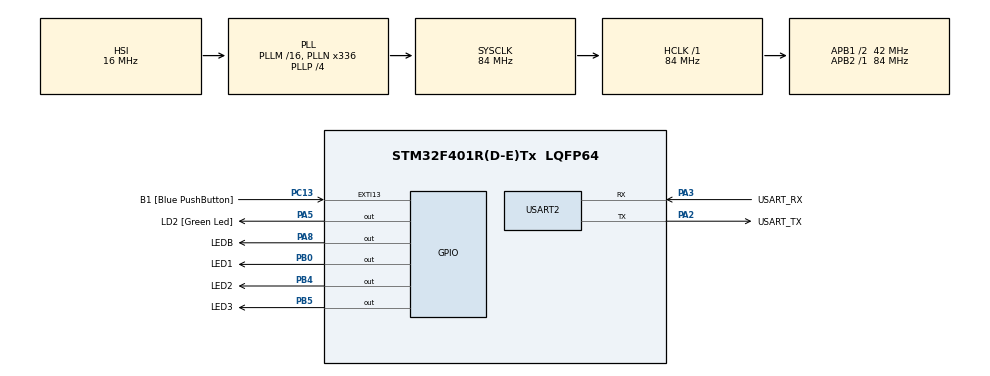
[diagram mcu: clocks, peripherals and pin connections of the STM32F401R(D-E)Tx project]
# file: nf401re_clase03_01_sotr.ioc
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Mcu.Family=STM32F4
PA2.GPIO_PuPd=GPIO_NOPULL
RCC.CortexFreq_Value=84000000
PA14.GPIO_Label=TCK
PA3.GPIO_PuPd=GPIO_NOPULL
PA2.GPIO_Speed=GPIO_SPEED_FREQ_LOW
PB0.GPIO_Label=LED1
PA3.GPIO_Speed=GPIO_SPEED_FREQ_LOW
RCC.SYSCLKSource=RCC_SYSCLKSOURCE_PLLCLK
ProjectManager.StackSize=0x400
VP_FREERTOS_VS_CMSIS_V2.Mode=CMSIS_V2
PH0\ -\ OSC_IN.Signal=RCC_OSC_IN
RCC.HCLKFreq_Value=84000000
RCC.APB2TimFreq_Value=84000000
RCC.AHBFreq_Value=84000000
RCC.HSE_VALUE=8000000
PC13-ANTI_TAMP.Signal=GPXTI13
PC14-OSC32_IN.Mode=LSE-External-Oscillator
PA14.Mode=Serial_Wire
VP_SYS_VS_tim1.Mode=TIM1
PA5.GPIO_PuPd=GPIO_NOPULL
PA8.Signal=GPIO_Output
Mcu.Package=LQFP64
NVIC.TimeBase=TIM1_UP_TIM10_IRQn
USART2.VirtualMode=VM_ASYNC
PA2.GPIO_Label=USART_TX
NVIC.TimeBaseIP=TIM1
PB5.GPIO_Label=LED3
RCC.APB1TimFreq_Value=84000000
PB4.Signal=GPIO_Output
PA3.Signal=USART2_RX
PA2.GPIO_Mode=GPIO_MODE_AF_PP
PB3.GPIO_Label=SWO
PC15-OSC32_OUT.Mode=LSE-External-Oscillator
FREERTOS.Tasks01=defaultTask,24,128,StartDefaultTask,Default,NULL,Dynamic,NULL,NULL
PC13-ANTI_TAMP.GPIO_PuPd=GPIO_NOPULL
PC13-ANTI_TAMP.GPIO_Label=B1 [Blue PushButton]
PH1\ -\ OSC_OUT.Mode=HSE-External-Clock-Source
RCC.APB1CLKDivider=RCC_HCLK_DIV2
PC14-OSC32_IN.Signal=RCC_OSC32_IN
PA13.Signal=SYS_JTMS-SWDIO
PA3.Mode=Asynchronous
PH0\ -\ OSC_IN.Mode=HSE-External-Clock-Source
PA8.GPIO_Label=LEDB
ProjectManager.TargetToolchain=STM32CubeIDE
PA3.GPIO_Mode=GPIO_MODE_AF_PP
PC15-OSC32_OUT.Signal=RCC_OSC32_OUT
PA5.Signal=GPIO_Output
PH1\ -\ OSC_OUT.Signal=RCC_OSC_OUT
board=NUCLEO-F401RE
RCC.VCOOutputFreq_Value=336000000
RCC.APB2Freq_Value=84000000
PB4.GPIO_Label=LED2
PA13.Mode=Serial_Wire
Mcu.Name=STM32F401R(D-E)Tx
PA13.GPIO_Label=TMS
PA2.Signal=USART2_TX
RCC.48MHZClocksFreq_Value=48000000
PB3.Signal=SYS_JTDO-SWO
RCC.SYSCLKFreq_VALUE=84000000
PB5.Signal=GPIO_Output
PA5.GPIO_Label=LD2 [Green Led]
PC13-ANTI_TAMP.GPIO_ModeDefaultEXTI=GPIO_MODE_IT_FALLING
PA14.Signal=SYS_JTCK-SWCLK
ProjectManager.HeapSize=0x200
NVIC.TIM1_UP_TIM10_IRQn=true\:0\:0\:false\:false\:true\:false\:false\:true
RCC.HSI_VALUE=16000000
RCC.PLLP=RCC_PLLP_DIV4
PA5.GPIO_Speed=GPIO_SPEED_FREQ_LOW
RCC.PLLQ=7
NVIC.PriorityGroup=NVIC_PRIORITYGROUP_4
RCC.PLLN=336
PA2.Mode=Asynchronous
RCC.APB1Freq_Value=42000000
PA5.GPIO_Mode=GPIO_MODE_OUTPUT_PP
PB0.Signal=GPIO_Output
PA3.GPIO_Label=USART_RX

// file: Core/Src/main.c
/* USER CODE BEGIN Header */
/**
  ******************************************************************************
  * @file           : main.c
  * @brief          : Main program body
  ******************************************************************************
  * @attention
  *
  * <h2><center>&copy; Copyright (c) 2021 STMicroelectronics.
  * All rights reserved.</center></h2>
  *
  * This software component is licensed by ST under BSD 3-Clause license,
  * the "License"; You may not use this file except in compliance with the
  * License. You may obtain a copy of the License at:
  *                        opensource.org/licenses/BSD-3-Clause
  *
  ******************************************************************************
  */
/* USER CODE END Header */
#include "main.h"
//#include "cmsis_os.h"

/* USER CODE BEGIN Includes */
#include "FreeRTOS.h"
#include "task.h"
#include "FreeRTOSConfig.h"
//#include "sapi.h"

/* USER CODE END Includes */

UART_HandleTypeDef huart2;

/* Definitions for defaultTask */
/*osThreadId_t defaultTaskHandle;
const osThreadAttr_t defaultTask_attributes = {
  .name = "defaultTask",
  .stack_size = 128 * 4,
  .priority = (osPriority_t) osPriorityNormal,
};*/

void SystemClock_Config(void);
static void MX_GPIO_Init(void);
static void MX_USART2_UART_Init(void);
void StartDefaultTask(void *argument);

/* USER CODE BEGIN PFP */
void heart_beat(void * parameters); /*Prendo A - apago A*/
/* USER CODE END PFP */

int main(void)
{

  /* MCU Configuration--------------------------------------------------------*/

  /* Reset of all peripherals, Initializes the Flash interface and the Systick. */
  HAL_Init();

  /* Configure the system clock */
  SystemClock_Config();

  /* Initialize all configured peripherals */
  MX_GPIO_Init();
  MX_USART2_UART_Init();

  /* Init scheduler */
  osKernelInitialize();

  /* Create the thread(s) */
  /* creation of defaultTask */
  /*defaultTaskHandle = osThreadNew(StartDefaultTask, NULL, &defaultTask_attributes);*/

  /* USER CODE BEGIN RTOS_THREADS */
  /* add threads, ... */
  BaseType_t res = xTaskCreate(heart_beat, (const char*) "heart_beat", 2*configMINIMAL_STACK_SIZE, 0, tskIDLE_PRIORITY+1, 0);
  if(res == pdFAIL){
	  HAL_GPIO_WritePin(LD2_GPIO_Port, LD2_Pin, GPIO_PIN_SET);
  }
  configASSERT(res == pdPASS);

  /* USER CODE END RTOS_THREADS */

  /* Start scheduler */
  osKernelStart();

  /* We should never get here as control is now taken by the scheduler */
  /* Infinite loop */
  while (1)
  {

  }
}

void SystemClock_Config(void)
{
  RCC_OscInitTypeDef RCC_OscInitStruct = {0};
  RCC_ClkInitTypeDef RCC_ClkInitStruct = {0};

  /** Configure the main internal regulator output voltage
  */
  __HAL_RCC_PWR_CLK_ENABLE();
  __HAL_PWR_VOLTAGESCALING_CONFIG(PWR_REGULATOR_VOLTAGE_SCALE2);
  /** Initializes the RCC Oscillators according to the specified parameters
  * in the RCC_OscInitTypeDef structure.
  */
  RCC_OscInitStruct.OscillatorType = RCC_OSCILLATORTYPE_HSI;
  RCC_OscInitStruct.HSIState = RCC_HSI_ON;
  RCC_OscInitStruct.HSICalibrationValue = RCC_HSICALIBRATION_DEFAULT;
  RCC_OscInitStruct.PLL.PLLState = RCC_PLL_ON;
  RCC_OscInitStruct.PLL.PLLSource = RCC_PLLSOURCE_HSI;
  RCC_OscInitStruct.PLL.PLLM = 16;
  RCC_OscInitStruct.PLL.PLLN = 336;
  RCC_OscInitStruct.PLL.PLLP = RCC_PLLP_DIV4;
  RCC_OscInitStruct.PLL.PLLQ = 7;
  if (HAL_RCC_OscConfig(&RCC_OscInitStruct) != HAL_OK)
  {
    Error_Handler();
  }
  /** Initializes the CPU, AHB and APB buses clocks
  */
  RCC_ClkInitStruct.ClockType = RCC_CLOCKTYPE_HCLK|RCC_CLOCKTYPE_SYSCLK
                              |RCC_CLOCKTYPE_PCLK1|RCC_CLOCKTYPE_PCLK2;
  RCC_ClkInitStruct.SYSCLKSource = RCC_SYSCLKSOURCE_PLLCLK;
  RCC_ClkInitStruct.AHBCLKDivider = RCC_SYSCLK_DIV1;
  RCC_ClkInitStruct.APB1CLKDivider = RCC_HCLK_DIV2;
  RCC_ClkInitStruct.APB2CLKDivider = RCC_HCLK_DIV1;

  if (HAL_RCC_ClockConfig(&RCC_ClkInitStruct, FLASH_LATENCY_2) != HAL_OK)
  {
    Error_Handler();
  }
}

static void MX_USART2_UART_Init(void)
{

  huart2.Instance = USART2;
  huart2.Init.BaudRate = 115200;
  huart2.Init.WordLength = UART_WORDLENGTH_8B;
  huart2.Init.StopBits = UART_STOPBITS_1;
  huart2.Init.Parity = UART_PARITY_NONE;
  huart2.Init.Mode = UART_MODE_TX_RX;
  huart2.Init.HwFlowCtl = UART_HWCONTROL_NONE;
  huart2.Init.OverSampling = UART_OVERSAMPLING_16;
  if (HAL_UART_Init(&huart2) != HAL_OK)
  {
    Error_Handler();
  }

}

static void MX_GPIO_Init(void)
{
  GPIO_InitTypeDef GPIO_InitStruct = {0};

  /* GPIO Ports Clock Enable */
  __HAL_RCC_GPIOC_CLK_ENABLE();
  __HAL_RCC_GPIOH_CLK_ENABLE();
  __HAL_RCC_GPIOA_CLK_ENABLE();
  __HAL_RCC_GPIOB_CLK_ENABLE();

  /*Configure GPIO pin Output Level */
  HAL_GPIO_WritePin(GPIOA, LD2_Pin|LEDB_Pin, GPIO_PIN_RESET);

  /*Configure GPIO pin Output Level */
  HAL_GPIO_WritePin(GPIOB, LED1_Pin|LED2_Pin|LED3_Pin, GPIO_PIN_RESET);

  /*Configure GPIO pin : B1_Pin */
  GPIO_InitStruct.Pin = B1_Pin;
  GPIO_InitStruct.Mode = GPIO_MODE_IT_FALLING;
  GPIO_InitStruct.Pull = GPIO_NOPULL;
  HAL_GPIO_Init(B1_GPIO_Port, &GPIO_InitStruct);

  /*Configure GPIO pins : LD2_Pin LEDB_Pin */
  GPIO_InitStruct.Pin = LD2_Pin|LEDB_Pin;
  GPIO_InitStruct.Mode = GPIO_MODE_OUTPUT_PP;
  GPIO_InitStruct.Pull = GPIO_NOPULL;
  GPIO_InitStruct.Speed = GPIO_SPEED_FREQ_LOW;
  HAL_GPIO_Init(GPIOA, &GPIO_InitStruct);

  /*Configure GPIO pins : LED1_Pin LED2_Pin LED3_Pin */
  GPIO_InitStruct.Pin = LED1_Pin|LED2_Pin|LED3_Pin;
  GPIO_InitStruct.Mode = GPIO_MODE_OUTPUT_PP;
  GPIO_InitStruct.Pull = GPIO_NOPULL;
  GPIO_InitStruct.Speed = GPIO_SPEED_FREQ_LOW;
  HAL_GPIO_Init(GPIOB, &GPIO_InitStruct);

}

/* USER CODE BEGIN 4 */
void heart_beat(void * parameters){
	/*Inicializacion*/

	/*Repetir por siempre*/
	for(;;){
		HAL_GPIO_WritePin(LEDB_GPIO_Port, LEDB_Pin, GPIO_PIN_SET);
		vTaskDelay(500 / portTICK_RATE_MS); 		 /*  portTICK_PERIOD_MS;  */
		HAL_GPIO_WritePin(LEDB_GPIO_Port, LEDB_Pin, GPIO_PIN_RESET);
		vTaskDelay(500 / portTICK_RATE_MS);
	}
}

/* USER CODE END 4 */

void StartDefaultTask(void *argument)
{
  for(;;)
  {
    osDelay(1);
  }
}

 /**
  * @brief  Period elapsed callback in non blocking mode
  * @note   This function is called  when TIM1 interrupt took place, inside
  * HAL_TIM_IRQHandler(). It makes a direct call to HAL_IncTick() to increment
  * a global variable "uwTick" used as application time base.
  * @param  htim : TIM handle
  * @retval None
  */
void HAL_TIM_PeriodElapsedCallback(TIM_HandleTypeDef *htim)
{
  if (htim->Instance == TIM1) {
    HAL_IncTick();
  }
}

void Error_Handler(void)
{
  __disable_irq();
  while (1)
  {
  }
}

/************************ (C) COPYRIGHT STMicroelectronics *****END OF FILE****/
